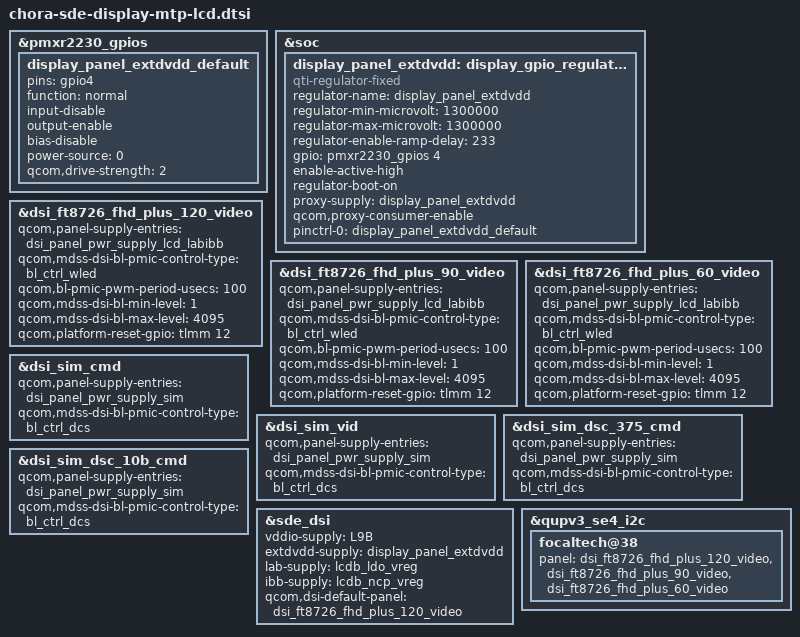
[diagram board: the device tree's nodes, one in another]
// SPDX-License-Identifier: BSD-3-Clause
/*
 * Copyright (c) Qualcomm Technologies, Inc. and/or its subsidiaries.
 */

#include "chora-sde-display.dtsi"

&pmxr2230_gpios {
	display_panel_extdvdd_default: display_panel_extdvdd_default {
		pins = "gpio4";
		function = "normal";
		input-disable;
		output-enable;
		bias-disable;
		power-source = <0>;
		qcom,drive-strength = <2>;
	};
};

&soc {
	display_panel_extdvdd: display_gpio_regulator@1 {
		compatible = "qti-regulator-fixed";
		regulator-name = "display_panel_extdvdd";
		regulator-min-microvolt = <1300000>;
		regulator-max-microvolt = <1300000>;
		regulator-enable-ramp-delay = <233>;
		gpio = <&pmxr2230_gpios 4 0>;
		enable-active-high;
		regulator-boot-on;
		proxy-supply = <&display_panel_extdvdd>;
		qcom,proxy-consumer-enable;
		pinctrl-names = "default";
		pinctrl-0 = <&display_panel_extdvdd_default>;
	};
};

&dsi_ft8726_fhd_plus_120_video {
	qcom,panel-supply-entries = <&dsi_panel_pwr_supply_lcd_labibb>;
	qcom,mdss-dsi-bl-pmic-control-type = "bl_ctrl_wled";
	qcom,bl-pmic-pwm-period-usecs = <100>;
	qcom,mdss-dsi-bl-min-level = <1>;
	qcom,mdss-dsi-bl-max-level = <4095>;
	qcom,platform-reset-gpio = <&tlmm 12 0>;
};

&dsi_ft8726_fhd_plus_90_video {
	qcom,panel-supply-entries = <&dsi_panel_pwr_supply_lcd_labibb>;
	qcom,mdss-dsi-bl-pmic-control-type = "bl_ctrl_wled";
	qcom,bl-pmic-pwm-period-usecs = <100>;
	qcom,mdss-dsi-bl-min-level = <1>;
	qcom,mdss-dsi-bl-max-level = <4095>;
	qcom,platform-reset-gpio = <&tlmm 12 0>;
};

&dsi_ft8726_fhd_plus_60_video {
	qcom,panel-supply-entries = <&dsi_panel_pwr_supply_lcd_labibb>;
	qcom,mdss-dsi-bl-pmic-control-type = "bl_ctrl_wled";
	qcom,bl-pmic-pwm-period-usecs = <100>;
	qcom,mdss-dsi-bl-min-level = <1>;
	qcom,mdss-dsi-bl-max-level = <4095>;
	qcom,platform-reset-gpio = <&tlmm 12 0>;
};

&dsi_sim_cmd {
	qcom,panel-supply-entries = <&dsi_panel_pwr_supply_sim>;
	qcom,mdss-dsi-bl-pmic-control-type = "bl_ctrl_dcs";
};

&dsi_sim_vid {
	qcom,panel-supply-entries = <&dsi_panel_pwr_supply_sim>;
	qcom,mdss-dsi-bl-pmic-control-type = "bl_ctrl_dcs";
};

&dsi_sim_dsc_375_cmd {
	qcom,panel-supply-entries = <&dsi_panel_pwr_supply_sim>;
	qcom,mdss-dsi-bl-pmic-control-type = "bl_ctrl_dcs";
};

&dsi_sim_dsc_10b_cmd {
	qcom,panel-supply-entries = <&dsi_panel_pwr_supply_sim>;
	qcom,mdss-dsi-bl-pmic-control-type = "bl_ctrl_dcs";
};

&sde_dsi {
	vddio-supply = <&L9B>;
	extdvdd-supply = <&display_panel_extdvdd>;
	lab-supply = <&lcdb_ldo_vreg>;
	ibb-supply = <&lcdb_ncp_vreg>;

	qcom,dsi-default-panel = <&dsi_ft8726_fhd_plus_120_video>;
};

&qupv3_se4_i2c {
	focaltech@38 {
		panel = <&dsi_ft8726_fhd_plus_120_video
			&dsi_ft8726_fhd_plus_90_video
			&dsi_ft8726_fhd_plus_60_video>;
	};
};
